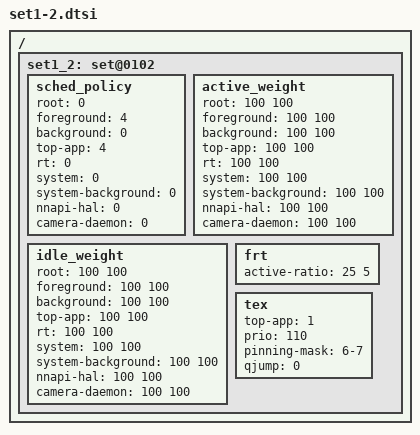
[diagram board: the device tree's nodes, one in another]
/ {
	/* power-scenario mode - app boost */
	set1_2: set@0102 {
		sched_policy {
			root = <0>;
			foreground = <4>;
			background = <0>;
			top-app = <4>;
			rt = <0>;
			system = <0>;
			system-background = <0>;
			nnapi-hal = <0>;
			camera-daemon = <0>;
		};

		active_weight {
			root = <100 100>;
			foreground = <100 100>;
			background = <100 100>;
			top-app = <100 100>;
			rt = <100 100>;
			system = <100 100>;
			system-background = <100 100>;
			nnapi-hal = <100 100>;
			camera-daemon = <100 100>;
		};

		idle_weight {
			root = <100 100>;
			foreground = <100 100>;
			background = <100 100>;
			top-app = <100 100>;
			rt = <100 100>;
			system = <100 100>;
			system-background = <100 100>;
			nnapi-hal = <100 100>;
			camera-daemon = <100 100>;
		};

		frt {	   			/* LIT BIG */
			active-ratio 		= < 25   5>;
		};

		tex {
			top-app		= <1>;
			prio		= <110>;
			pinning-mask	= "6-7";
			qjump		= <0>;
		};
	};
};
